AUTOSAR XML (schema 4-0-3)
package /AppMode/ApplicationSwComponentTypes
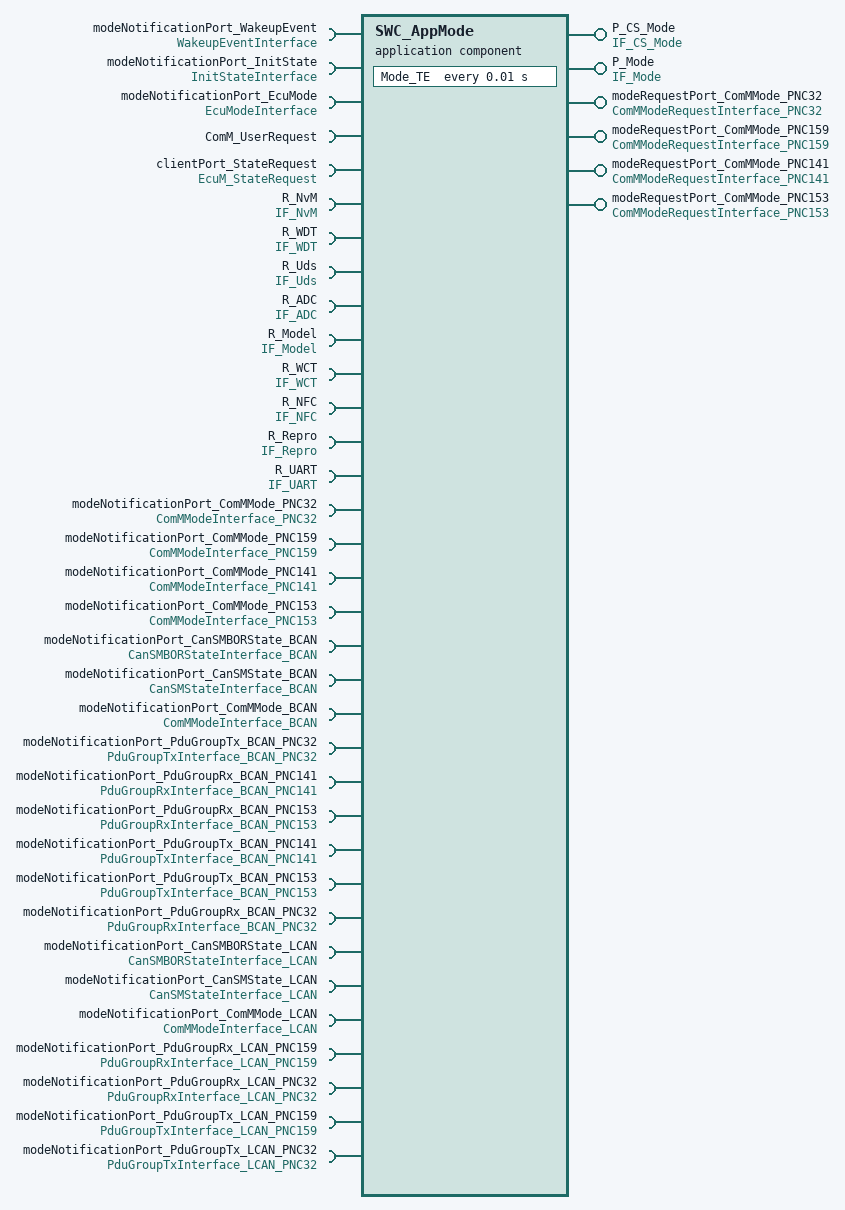
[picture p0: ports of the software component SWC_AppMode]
  application sw component type SWC_AppMode
    8 x require port:
      modeNotificationPort_WakeupEvent: mode-switch-receiver-com-spec{enhanced-mode-api=true, mode-group=WakeupEvent, supports-asynchronous-mode-switch=true}, required-interface=WakeupEventInterface
      modeNotificationPort_InitState: mode-switch-receiver-com-spec{enhanced-mode-api=true, mode-group=InitState, supports-asynchronous-mode-switch=true}, required-interface=InitStateInterface
      modeNotificationPort_EcuMode: mode-switch-receiver-com-spec{enhanced-mode-api=true, mode-group=EcuMode, supports-asynchronous-mode-switch=true}, required-interface=EcuModeInterface
      ComM_UserRequest: client-com-spec=GetCurrentComMode, required-interface=ComM_UserRequest
      clientPort_StateRequest: required-com-specs=[ReleaseRUN, RequestRUN, RequestSleep, RequestReset, RequestOff, SetRunState], required-interface=EcuM_StateRequest
      R_NvM: nonqueued-receiver-com-spec=NvM_STR, required-interface=IF_NvM
      R_WDT: nonqueued-receiver-com-spec=WDT_STR, required-interface=IF_WDT
      R_Uds: nonqueued-receiver-com-spec=Uds_STR, required-interface=IF_Uds
    provide port P_CS_Mode: provided-interface=IF_CS_Mode
      provided-com-specs:
        operation=ModeInit, queue-length=1
        operation=NvMInit, queue-length=1
        operation=ApplicationInit, queue-length=1
    provide port P_Mode: nonqueued-sender-com-spec=Mode_STR, provided-interface=IF_Mode
    7 x require port:
      R_ADC: nonqueued-receiver-com-spec=ADC_STR, required-interface=IF_ADC
      R_Model: nonqueued-receiver-com-spec=Model_STR, required-interface=IF_Model
      R_WCT: nonqueued-receiver-com-spec=WCT_STR, required-interface=IF_WCT
      R_NFC: nonqueued-receiver-com-spec=NFC_STR, required-interface=IF_NFC
      R_Repro: nonqueued-receiver-com-spec=Repro_STR, required-interface=IF_Repro
      R_UART: nonqueued-receiver-com-spec=UART_STR, required-interface=IF_UART
      modeNotificationPort_ComMMode_PNC32: mode-switch-receiver-com-spec{enhanced-mode-api=true, mode-group=ComMMode_PNC32, supports-asynchronous-mode-switch=true}, required-interface=ComMModeInterface_PNC32
    provide port modeRequestPort_ComMMode_PNC32: nonqueued-sender-com-spec=ComMMode_PNC32, provided-interface=ComMModeRequestInterface_PNC32
    require port modeNotificationPort_ComMMode_PNC159: mode-switch-receiver-com-spec{enhanced-mode-api=true, mode-group=ComMMode_PNC159, supports-asynchronous-mode-switch=true}, required-interface=ComMModeInterface_PNC159
    provide port modeRequestPort_ComMMode_PNC159: nonqueued-sender-com-spec=ComMMode_PNC159, provided-interface=ComMModeRequestInterface_PNC159
    require port modeNotificationPort_ComMMode_PNC141: mode-switch-receiver-com-spec{enhanced-mode-api=true, mode-group=ComMMode_PNC141, supports-asynchronous-mode-switch=true}, required-interface=ComMModeInterface_PNC141
    require port modeNotificationPort_ComMMode_PNC153: mode-switch-receiver-com-spec{enhanced-mode-api=true, mode-group=ComMMode_PNC153, supports-asynchronous-mode-switch=true}, required-interface=ComMModeInterface_PNC153
    provide port modeRequestPort_ComMMode_PNC141: nonqueued-sender-com-spec=ComMMode_PNC141, provided-interface=ComMModeRequestInterface_PNC141
    provide port modeRequestPort_ComMMode_PNC153: nonqueued-sender-com-spec=ComMMode_PNC153, provided-interface=ComMModeRequestInterface_PNC153
    16 x require port:
      modeNotificationPort_CanSMBORState_BCAN: mode-switch-receiver-com-spec{enhanced-mode-api=true, mode-group=CanSMBORState_BCAN, supports-asynchronous-mode-switch=true}, required-interface=CanSMBORStateInterface_BCAN
      modeNotificationPort_CanSMState_BCAN: mode-switch-receiver-com-spec{enhanced-mode-api=true, mode-group=CanSMState_BCAN, supports-asynchronous-mode-switch=true}, required-interface=CanSMStateInterface_BCAN
      modeNotificationPort_ComMMode_BCAN: mode-switch-receiver-com-spec{enhanced-mode-api=true, mode-group=ComMMode_BCAN, supports-asynchronous-mode-switch=true}, required-interface=ComMModeInterface_BCAN
      modeNotificationPort_PduGroupTx_BCAN_PNC32: mode-switch-receiver-com-spec{enhanced-mode-api=true, mode-group=PduGroupTx_BCAN_PNC32, supports-asynchronous-mode-switch=true}, required-interface=PduGroupTxInterface_BCAN_PNC32
      modeNotificationPort_PduGroupRx_BCAN_PNC141: mode-switch-receiver-com-spec{enhanced-mode-api=true, mode-group=PduGroupRx_BCAN_PNC141, supports-asynchronous-mode-switch=true}, required-interface=PduGroupRxInterface_BCAN_PNC141
      modeNotificationPort_PduGroupRx_BCAN_PNC153: mode-switch-receiver-com-spec{enhanced-mode-api=true, mode-group=PduGroupRx_BCAN_PNC153, supports-asynchronous-mode-switch=true}, required-interface=PduGroupRxInterface_BCAN_PNC153
      modeNotificationPort_PduGroupTx_BCAN_PNC141: mode-switch-receiver-com-spec{enhanced-mode-api=true, mode-group=PduGroupTx_BCAN_PNC141, supports-asynchronous-mode-switch=true}, required-interface=PduGroupTxInterface_BCAN_PNC141
      modeNotificationPort_PduGroupTx_BCAN_PNC153: mode-switch-receiver-com-spec{enhanced-mode-api=true, mode-group=PduGroupTx_BCAN_PNC153, supports-asynchronous-mode-switch=true}, required-interface=PduGroupTxInterface_BCAN_PNC153
      modeNotificationPort_PduGroupRx_BCAN_PNC32: mode-switch-receiver-com-spec{enhanced-mode-api=true, mode-group=PduGroupRx_BCAN_PNC32, supports-asynchronous-mode-switch=true}, required-interface=PduGroupRxInterface_BCAN_PNC32
      modeNotificationPort_CanSMBORState_LCAN: mode-switch-receiver-com-spec{enhanced-mode-api=true, mode-group=CanSMBORState_LCAN, supports-asynchronous-mode-switch=true}, required-interface=CanSMBORStateInterface_LCAN
      modeNotificationPort_CanSMState_LCAN: mode-switch-receiver-com-spec{enhanced-mode-api=true, mode-group=CanSMState_LCAN, supports-asynchronous-mode-switch=true}, required-interface=CanSMStateInterface_LCAN
      modeNotificationPort_ComMMode_LCAN: mode-switch-receiver-com-spec{enhanced-mode-api=true, mode-group=ComMMode_LCAN, supports-asynchronous-mode-switch=true}, required-interface=ComMModeInterface_LCAN
      modeNotificationPort_PduGroupRx_LCAN_PNC159: mode-switch-receiver-com-spec{enhanced-mode-api=true, mode-group=PduGroupRx_LCAN_PNC159, supports-asynchronous-mode-switch=true}, required-interface=PduGroupRxInterface_LCAN_PNC159
      modeNotificationPort_PduGroupRx_LCAN_PNC32: mode-switch-receiver-com-spec{enhanced-mode-api=true, mode-group=PduGroupRx_LCAN_PNC32, supports-asynchronous-mode-switch=true}, required-interface=PduGroupRxInterface_LCAN_PNC32
      modeNotificationPort_PduGroupTx_LCAN_PNC159: mode-switch-receiver-com-spec{enhanced-mode-api=true, mode-group=PduGroupTx_LCAN_PNC159, supports-asynchronous-mode-switch=true}, required-interface=PduGroupTxInterface_LCAN_PNC159
      modeNotificationPort_PduGroupTx_LCAN_PNC32: mode-switch-receiver-com-spec{enhanced-mode-api=true, mode-group=PduGroupTx_LCAN_PNC32, supports-asynchronous-mode-switch=true}, required-interface=PduGroupTxInterface_LCAN_PNC32
    behavior SwcIB_AppMode: data-type-mapping=[MAP_CanSMBORState, MAP_ComMMode_PNC, EcuModeMap, MAP_InitState, MAP_PduGroup, MAP_WakeupEvent, MAP_ComMMode, DataTypeMappingSet_WPC]
      23 x swc mode switch event, all with activation=ON-ENTRY:
        SMSE_Entry_BusOffStateSwitched_modeNotificationPort_CanSMBORState_BCAN_CanSMBORState_BCAN_COMPLETE: start-on-event=CanSMBORStateSwitched_BCAN, mode=modeNotificationPort_CanSMBORState_BCAN.CanSMBORState_BCAN.COMPLETE
        SMSE_Entry_BusOffStateSwitched_modeNotificationPort_CanSMBORState_BCAN_CanSMBORState_BCAN_START: start-on-event=CanSMBORStateSwitched_BCAN, mode=modeNotificationPort_CanSMBORState_BCAN.CanSMBORState_BCAN.START
        SMSE_Entry_BusOffStateSwitched_modeNotificationPort_CanSMBORState_LCAN_CanSMBORState_LCAN_COMPLETE: start-on-event=CanSMBORStateSwitched_LCAN, mode=modeNotificationPort_CanSMBORState_LCAN.CanSMBORState_LCAN.COMPLETE
        SMSE_Entry_BusOffStateSwitched_modeNotificationPort_CanSMBORState_LCAN_CanSMBORState_LCAN_START: start-on-event=CanSMBORStateSwitched_LCAN, mode=modeNotificationPort_CanSMBORState_LCAN.CanSMBORState_LCAN.START
        SMSE_Entry_ComMModeSwitched_PNC141_modeNotificationPort_ComMMode_PNC141_ComMMode_PNC141_PNC_REQUESTED: start-on-event=ComMModeSwitched_PNC141, mode=modeNotificationPort_ComMMode_PNC141.ComMMode_PNC141.PNC_REQUESTED
        SMSE_Entry_ComMModeSwitched_PNC141_modeNotificationPort_ComMMode_PNC141_ComMMode_PNC141_PNC_READY_SLEEP: start-on-event=ComMModeSwitched_PNC141, mode=modeNotificationPort_ComMMode_PNC141.ComMMode_PNC141.PNC_READY_SLEEP
        SMSE_Entry_ComMModeSwitched_PNC141_modeNotificationPort_ComMMode_PNC141_ComMMode_PNC141_PNC_PREPARE_SLEEP: start-on-event=ComMModeSwitched_PNC141, mode=modeNotificationPort_ComMMode_PNC141.ComMMode_PNC141.PNC_PREPARE_SLEEP
        SMSE_Entry_ComMModeSwitched_PNC141_modeNotificationPort_ComMMode_PNC141_ComMMode_PNC141_PNC_NO_COMMUNICATION: start-on-event=ComMModeSwitched_PNC141, mode=modeNotificationPort_ComMMode_PNC141.ComMMode_PNC141.PNC_NO_COMMUNICATION
        SMSE_Entry_EcuModeSwitched_modeNotificationPort_EcuMode_EcuMode_ECUM_STATE_RUN: start-on-event=EcuModeSwitched, mode=modeNotificationPort_EcuMode.EcuMode.ECUM_STATE_RUN
        SMSE_Entry_EcuModeSwitched_modeNotificationPort_EcuMode_EcuMode_ECUM_STATE_SHUTDOWN: start-on-event=EcuModeSwitched, mode=modeNotificationPort_EcuMode.EcuMode.ECUM_STATE_SHUTDOWN
        SMSE_Entry_EcuModeSwitched_modeNotificationPort_EcuMode_EcuMode_ECUM_STATE_PREP_SHUTDOWN: start-on-event=EcuModeSwitched, mode=modeNotificationPort_EcuMode.EcuMode.ECUM_STATE_PREP_SHUTDOWN
        SMSE_Entry_EcuModeSwitched_modeNotificationPort_EcuMode_EcuMode_ECUM_STATE_SLEEP: start-on-event=EcuModeSwitched, mode=modeNotificationPort_EcuMode.EcuMode.ECUM_STATE_SLEEP
        SMSE_Entry_EcuModeSwitched_modeNotificationPort_EcuMode_EcuMode_ECUM_STATE_OFF: start-on-event=EcuModeSwitched, mode=modeNotificationPort_EcuMode.EcuMode.ECUM_STATE_OFF
        SMSE_Entry_EcuModeSwitched_modeNotificationPort_EcuMode_EcuMode_ECUM_STATE_RESET: start-on-event=EcuModeSwitched, mode=modeNotificationPort_EcuMode.EcuMode.ECUM_STATE_RESET
        SMSE_Entry_InitCompleted_modeNotificationPort_InitState_InitState_COMPLETE: start-on-event=InitCompleted, mode=modeNotificationPort_InitState.InitState.COMPLETE
        SMSE_Entry_PduGroupSwitched_BCAN_PNC141_Rx_modeNotificationPort_PduGroupRx_BCAN_PNC141_PduGroupRx_BCAN_PNC141_STOP: start-on-event=PduGroupSwitched_BCAN_PNC141_Rx, mode=modeNotificationPort_PduGroupRx_BCAN_PNC141.PduGroupRx_BCAN_PNC141.STOP
        SMSE_Entry_PduGroupSwitched_BCAN_PNC141_Rx_modeNotificationPort_PduGroupRx_BCAN_PNC141_PduGroupRx_BCAN_PNC141_START: start-on-event=PduGroupSwitched_BCAN_PNC141_Rx, mode=modeNotificationPort_PduGroupRx_BCAN_PNC141.PduGroupRx_BCAN_PNC141.START
        SMSE_Entry_PduGroupSwitched_BCAN_PNC141_Tx_modeNotificationPort_PduGroupTx_BCAN_PNC141_PduGroupTx_BCAN_PNC141_STOP: start-on-event=PduGroupSwitched_BCAN_PNC141_Tx, mode=modeNotificationPort_PduGroupTx_BCAN_PNC141.PduGroupTx_BCAN_PNC141.STOP
        SMSE_Entry_PduGroupSwitched_BCAN_PNC141_Tx_modeNotificationPort_PduGroupTx_BCAN_PNC141_PduGroupTx_BCAN_PNC141_START: start-on-event=PduGroupSwitched_BCAN_PNC141_Tx, mode=modeNotificationPort_PduGroupTx_BCAN_PNC141.PduGroupTx_BCAN_PNC141.START
        SMSE_Entry_WakeupEventValidated_modeNotificationPort_WakeupEvent_WakeupEvent_BCAN_RX: start-on-event=WakeupEventValidated, mode=modeNotificationPort_WakeupEvent.WakeupEvent.BCAN_RX
        SMSE_Entry_WakeupEventValidated_modeNotificationPort_WakeupEvent_WakeupEvent_BCAN_RX_POLL: start-on-event=WakeupEventValidated, mode=modeNotificationPort_WakeupEvent.WakeupEvent.BCAN_RX_POLL
        SMSE_Entry_WakeupEventValidated_modeNotificationPort_WakeupEvent_WakeupEvent_LCAN_RX: start-on-event=WakeupEventValidated, mode=modeNotificationPort_WakeupEvent.WakeupEvent.LCAN_RX
        SMSE_Entry_WakeupEventValidated_modeNotificationPort_WakeupEvent_WakeupEvent_LCAN_RX_POLL: start-on-event=WakeupEventValidated, mode=modeNotificationPort_WakeupEvent.WakeupEvent.LCAN_RX_POLL
      timing event TE_Mode_TE: start-on-event=Mode_TE, period=0.01
      15 x swc mode switch event, all with activation=ON-ENTRY:
        SMSE_Entry_ComMModeSwitched_PNC153_modeNotificationPort_ComMMode_PNC153_ComMMode_PNC153_PNC_FULL_COMMUNICATION: start-on-event=ComMModeSwitched_PNC153, mode=modeNotificationPort_ComMMode_PNC153.ComMMode_PNC153.PNC_FULL_COMMUNICATION
        SMSE_Entry_ComMModeSwitched_PNC153_modeNotificationPort_ComMMode_PNC153_ComMMode_PNC153_PNC_NO_COMMUNICATION: start-on-event=ComMModeSwitched_PNC153, mode=modeNotificationPort_ComMMode_PNC153.ComMMode_PNC153.PNC_NO_COMMUNICATION
        SMSE_Entry_ComMModeSwitched_PNC153_modeNotificationPort_ComMMode_PNC153_ComMMode_PNC153_PNC_PREPARE_SLEEP: start-on-event=ComMModeSwitched_PNC153, mode=modeNotificationPort_ComMMode_PNC153.ComMMode_PNC153.PNC_PREPARE_SLEEP
        SMSE_Entry_ComMModeSwitched_PNC153_modeNotificationPort_ComMMode_PNC153_ComMMode_PNC153_PNC_READY_SLEEP: start-on-event=ComMModeSwitched_PNC153, mode=modeNotificationPort_ComMMode_PNC153.ComMMode_PNC153.PNC_READY_SLEEP
        SMSE_Entry_ComMModeSwitched_PNC153_modeNotificationPort_ComMMode_PNC153_ComMMode_PNC153_PNC_REQUESTED: start-on-event=ComMModeSwitched_PNC153, mode=modeNotificationPort_ComMMode_PNC153.ComMMode_PNC153.PNC_REQUESTED
        SMSE_Entry_PduGroupSwitched_BCAN_PNC153_Rx_modeNotificationPort_PduGroupRx_BCAN_PNC153_PduGroupRx_BCAN_PNC153_START: start-on-event=PduGroupSwitched_BCAN_PNC153_Rx, mode=modeNotificationPort_PduGroupRx_BCAN_PNC153.PduGroupRx_BCAN_PNC153.START
        SMSE_Entry_PduGroupSwitched_BCAN_PNC153_Rx_modeNotificationPort_PduGroupRx_BCAN_PNC153_PduGroupRx_BCAN_PNC153_STOP: start-on-event=PduGroupSwitched_BCAN_PNC153_Rx, mode=modeNotificationPort_PduGroupRx_BCAN_PNC153.PduGroupRx_BCAN_PNC153.STOP
        SMSE_Entry_PduGroupSwitched_BCAN_PNC153_Tx_modeNotificationPort_PduGroupTx_BCAN_PNC153_PduGroupTx_BCAN_PNC153_START: start-on-event=PduGroupSwitched_BCAN_PNC153_Tx, mode=modeNotificationPort_PduGroupTx_BCAN_PNC153.PduGroupTx_BCAN_PNC153.START
        SMSE_Entry_PduGroupSwitched_BCAN_PNC153_Tx_modeNotificationPort_PduGroupTx_BCAN_PNC153_PduGroupTx_BCAN_PNC153_STOP: start-on-event=PduGroupSwitched_BCAN_PNC153_Tx, mode=modeNotificationPort_PduGroupTx_BCAN_PNC153.PduGroupTx_BCAN_PNC153.STOP
        SMSE_Entry_ComMModeSwitched_BCAN_modeNotificationPort_ComMMode_BCAN_ComMMode_BCAN_FULL_COM: start-on-event=ComMModeSwitched_BCAN, mode=modeNotificationPort_ComMMode_BCAN.ComMMode_BCAN.FULL_COM
        SMSE_Entry_ComMModeSwitched_BCAN_modeNotificationPort_ComMMode_BCAN_ComMMode_BCAN_NO_COM: start-on-event=ComMModeSwitched_BCAN, mode=modeNotificationPort_ComMMode_BCAN.ComMMode_BCAN.NO_COM
        SMSE_Entry_ComMModeSwitched_BCAN_modeNotificationPort_ComMMode_BCAN_ComMMode_BCAN_SILENT_COM: start-on-event=ComMModeSwitched_BCAN, mode=modeNotificationPort_ComMMode_BCAN.ComMMode_BCAN.SILENT_COM
        SMSE_Entry_ComMModeSwitched_LCAN_modeNotificationPort_ComMMode_LCAN_ComMMode_LCAN_FULL_COM: start-on-event=ComMModeSwitched_LCAN, mode=modeNotificationPort_ComMMode_LCAN.ComMMode_LCAN.FULL_COM
        SMSE_Entry_ComMModeSwitched_LCAN_modeNotificationPort_ComMMode_LCAN_ComMMode_LCAN_NO_COM: start-on-event=ComMModeSwitched_LCAN, mode=modeNotificationPort_ComMMode_LCAN.ComMMode_LCAN.NO_COM
        SMSE_Entry_ComMModeSwitched_LCAN_modeNotificationPort_ComMMode_LCAN_ComMMode_LCAN_SILENT_COM: start-on-event=ComMModeSwitched_LCAN, mode=modeNotificationPort_ComMMode_LCAN.ComMMode_LCAN.SILENT_COM
      operation invoked event OIE_Mode_CS_ApplicationInit_P_CS_Mode_ApplicationInit: start-on-event=Mode_CS_ApplicationInit, operation=P_CS_Mode.ApplicationInit
      operation invoked event OIE_Mode_CS_ModeInit_P_CS_Mode_ModeInit: start-on-event=Mode_CS_ModeInit, operation=P_CS_Mode.ModeInit
      operation invoked event OIE_Mode_CS_NvMInit_P_CS_Mode_NvMInit: start-on-event=Mode_CS_NvMInit, operation=P_CS_Mode.NvMInit
      24 x swc mode switch event, all with activation=ON-ENTRY:
        SMSE_Entry_WakeupEventValidated_modeNotificationPort_WakeupEvent_WakeupEvent_IGN1: start-on-event=WakeupEventValidated, mode=modeNotificationPort_WakeupEvent.WakeupEvent.IGN1
        SMSE_Entry_ComMModeSwitched_PNC159_modeNotificationPort_ComMMode_PNC159_ComMMode_PNC159_PNC_FULL_COMMUNICATION: start-on-event=ComMModeSwitched_PNC159, mode=modeNotificationPort_ComMMode_PNC159.ComMMode_PNC159.PNC_FULL_COMMUNICATION
        SMSE_Entry_ComMModeSwitched_PNC159_modeNotificationPort_ComMMode_PNC159_ComMMode_PNC159_PNC_NO_COMMUNICATION: start-on-event=ComMModeSwitched_PNC159, mode=modeNotificationPort_ComMMode_PNC159.ComMMode_PNC159.PNC_NO_COMMUNICATION
        SMSE_Entry_ComMModeSwitched_PNC159_modeNotificationPort_ComMMode_PNC159_ComMMode_PNC159_PNC_PREPARE_SLEEP: start-on-event=ComMModeSwitched_PNC159, mode=modeNotificationPort_ComMMode_PNC159.ComMMode_PNC159.PNC_PREPARE_SLEEP
        SMSE_Entry_ComMModeSwitched_PNC159_modeNotificationPort_ComMMode_PNC159_ComMMode_PNC159_PNC_READY_SLEEP: start-on-event=ComMModeSwitched_PNC159, mode=modeNotificationPort_ComMMode_PNC159.ComMMode_PNC159.PNC_READY_SLEEP
        SMSE_Entry_ComMModeSwitched_PNC159_modeNotificationPort_ComMMode_PNC159_ComMMode_PNC159_PNC_REQUESTED: start-on-event=ComMModeSwitched_PNC159, mode=modeNotificationPort_ComMMode_PNC159.ComMMode_PNC159.PNC_REQUESTED
        SMSE_Entry_ComMModeSwitched_PNC141_modeNotificationPort_ComMMode_PNC141_ComMMode_PNC141_PNC_FULL_COMMUNICATION: start-on-event=ComMModeSwitched_PNC141, mode=modeNotificationPort_ComMMode_PNC141.ComMMode_PNC141.PNC_FULL_COMMUNICATION
        SMSE_Entry_PduGroupSwitched_LCAN_PNC159_Rx_modeNotificationPort_PduGroupRx_LCAN_PNC159_PduGroupRx_LCAN_PNC159_START: start-on-event=PduGroupSwitched_LCAN_PNC159_Rx, mode=modeNotificationPort_PduGroupRx_LCAN_PNC159.PduGroupRx_LCAN_PNC159.START
        SMSE_Entry_PduGroupSwitched_LCAN_PNC159_Rx_modeNotificationPort_PduGroupRx_LCAN_PNC159_PduGroupRx_LCAN_PNC159_STOP: start-on-event=PduGroupSwitched_LCAN_PNC159_Rx, mode=modeNotificationPort_PduGroupRx_LCAN_PNC159.PduGroupRx_LCAN_PNC159.STOP
        SMSE_Entry_PduGroupSwitched_LCAN_PNC159_Tx_modeNotificationPort_PduGroupTx_LCAN_PNC159_PduGroupTx_LCAN_PNC159_START: start-on-event=PduGroupSwitched_LCAN_PNC159_Tx, mode=modeNotificationPort_PduGroupTx_LCAN_PNC159.PduGroupTx_LCAN_PNC159.START
        SMSE_Entry_PduGroupSwitched_LCAN_PNC159_Tx_modeNotificationPort_PduGroupTx_LCAN_PNC159_PduGroupTx_LCAN_PNC159_STOP: start-on-event=PduGroupSwitched_LCAN_PNC159_Tx, mode=modeNotificationPort_PduGroupTx_LCAN_PNC159.PduGroupTx_LCAN_PNC159.STOP
        SMSE_Entry_ComMModeSwitched_PNC32_modeNotificationPort_ComMMode_PNC32_ComMMode_PNC32_PNC_FULL_COMMUNICATION: start-on-event=ComMModeSwitched_PNC32, mode=modeNotificationPort_ComMMode_PNC32.ComMMode_PNC32.PNC_FULL_COMMUNICATION
        SMSE_Entry_ComMModeSwitched_PNC32_modeNotificationPort_ComMMode_PNC32_ComMMode_PNC32_PNC_NO_COMMUNICATION: start-on-event=ComMModeSwitched_PNC32, mode=modeNotificationPort_ComMMode_PNC32.ComMMode_PNC32.PNC_NO_COMMUNICATION
        SMSE_Entry_ComMModeSwitched_PNC32_modeNotificationPort_ComMMode_PNC32_ComMMode_PNC32_PNC_PREPARE_SLEEP: start-on-event=ComMModeSwitched_PNC32, mode=modeNotificationPort_ComMMode_PNC32.ComMMode_PNC32.PNC_PREPARE_SLEEP
        SMSE_Entry_ComMModeSwitched_PNC32_modeNotificationPort_ComMMode_PNC32_ComMMode_PNC32_PNC_READY_SLEEP: start-on-event=ComMModeSwitched_PNC32, mode=modeNotificationPort_ComMMode_PNC32.ComMMode_PNC32.PNC_READY_SLEEP
        SMSE_Entry_ComMModeSwitched_PNC32_modeNotificationPort_ComMMode_PNC32_ComMMode_PNC32_PNC_REQUESTED: start-on-event=ComMModeSwitched_PNC32, mode=modeNotificationPort_ComMMode_PNC32.ComMMode_PNC32.PNC_REQUESTED
        SMSE_Entry_PduGroupSwitched_BCAN_PNC32_Rx_modeNotificationPort_PduGroupRx_BCAN_PNC32_PduGroupRx_BCAN_PNC32_START: start-on-event=PduGroupSwitched_BCAN_PNC32_Rx, mode=modeNotificationPort_PduGroupRx_BCAN_PNC32.PduGroupRx_BCAN_PNC32.START
        SMSE_Entry_PduGroupSwitched_BCAN_PNC32_Rx_modeNotificationPort_PduGroupRx_BCAN_PNC32_PduGroupRx_BCAN_PNC32_STOP: start-on-event=PduGroupSwitched_BCAN_PNC32_Rx, mode=modeNotificationPort_PduGroupRx_BCAN_PNC32.PduGroupRx_BCAN_PNC32.STOP
        SMSE_Entry_PduGroupSwitched_BCAN_PNC32_Tx_modeNotificationPort_PduGroupTx_BCAN_PNC32_PduGroupTx_BCAN_PNC32_START: start-on-event=PduGroupSwitched_BCAN_PNC32_Tx, mode=modeNotificationPort_PduGroupTx_BCAN_PNC32.PduGroupTx_BCAN_PNC32.START
        SMSE_Entry_PduGroupSwitched_BCAN_PNC32_Tx_modeNotificationPort_PduGroupTx_BCAN_PNC32_PduGroupTx_BCAN_PNC32_STOP: start-on-event=PduGroupSwitched_BCAN_PNC32_Tx, mode=modeNotificationPort_PduGroupTx_BCAN_PNC32.PduGroupTx_BCAN_PNC32.STOP
        SMSE_Entry_PduGroupSwitched_LCAN_PNC32_Tx_modeNotificationPort_PduGroupTx_LCAN_PNC32_PduGroupTx_LCAN_PNC32_START: start-on-event=PduGroupSwitched_LCAN_PNC32_Tx, mode=modeNotificationPort_PduGroupTx_LCAN_PNC32.PduGroupTx_LCAN_PNC32.START
        SMSE_Entry_PduGroupSwitched_LCAN_PNC32_Tx_modeNotificationPort_PduGroupTx_LCAN_PNC32_PduGroupTx_LCAN_PNC32_STOP: start-on-event=PduGroupSwitched_LCAN_PNC32_Tx, mode=modeNotificationPort_PduGroupTx_LCAN_PNC32.PduGroupTx_LCAN_PNC32.STOP
        SMSE_Entry_PduGroupSwitched_LCAN_PNC32_Rx_modeNotificationPort_PduGroupRx_LCAN_PNC32_PduGroupRx_LCAN_PNC32_START: start-on-event=PduGroupSwitched_LCAN_PNC32_Rx, mode=modeNotificationPort_PduGroupRx_LCAN_PNC32.PduGroupRx_LCAN_PNC32.START
        SMSE_Entry_PduGroupSwitched_LCAN_PNC32_Rx_modeNotificationPort_PduGroupRx_LCAN_PNC32_PduGroupRx_LCAN_PNC32_STOP: start-on-event=PduGroupSwitched_LCAN_PNC32_Rx, mode=modeNotificationPort_PduGroupRx_LCAN_PNC32.PduGroupRx_LCAN_PNC32.STOP
      25 x runnable:
        Mode_TE: symbol=Mode_TE_Runnable
          data-receive-point-by-arguments:
            9 x access, all with scope=COMMUNICATION-INTER-ECU:
              DRPBA_Mode_TE_R_ADC_ADC_STR: accessed-variable=R_ADC.ADC_STR
              DRPBA_Mode_TE_R_Model_Model_COMM_STR: accessed-variable=R_Model.Model_STR
              DRPBA_Mode_TE_R_NFC_NFC2_STR: accessed-variable=R_NFC.NFC_STR
              DRPBA_Mode_TE_R_WCT_WCT_STR: accessed-variable=R_WCT.WCT_STR
              DRPBA_Mode_TE_R_Uds_Uds_STR: accessed-variable=R_Uds.Uds_STR
              DRPBA_Mode_TE_R_WDT_WDT_STR: accessed-variable=R_WDT.WDT_STR
              DRPBA_Mode_TE_R_Repro_Repro_STR: accessed-variable=R_Repro.Repro_STR
              DRPBA_Mode_TE_R_NvM_NvM_STR: accessed-variable=R_NvM.NvM_STR
              DRPBA_Mode_TE_R_UART_UART_STR: accessed-variable=R_UART.UART_STR
          data-send-points:
            4 x access, all with scope=COMMUNICATION-INTER-ECU:
              DSP_Mode_TE_modeRequestPort_ComMMode_PNC141_ComMMode_PNC141: accessed-variable=modeRequestPort_ComMMode_PNC141.ComMMode_PNC141
              DSP_Mode_TE_modeRequestPort_ComMMode_PNC153_ComMMode_PNC153: accessed-variable=modeRequestPort_ComMMode_PNC153.ComMMode_PNC153
              DSP_Mode_TE_P_Mode_Mode_STR: accessed-variable=P_Mode.Mode_STR
              DSP_Mode_TE_modeRequestPort_ComMMode_PNC159_ComMMode_PNC159: accessed-variable=modeRequestPort_ComMMode_PNC159.ComMMode_PNC159
          9 x sync call:
            SSCP_Mode_TE_ComM_UserRequest_GetCurrentComMode: operation=ComM_UserRequest.GetCurrentComMode
            SSCP_Mode_TE_ComM_UserRequest_GetRequestedComMode: operation=ComM_UserRequest.GetRequestedComMode
            SSCP_Mode_TE_ComM_UserRequest_RequestComMode: operation=ComM_UserRequest.RequestComMode
            SSCP_Mode_TE_clientPort_StateRequest_ReleaseRUN: operation=clientPort_StateRequest.ReleaseRUN
            SSCP_Mode_TE_clientPort_StateRequest_RequestOff: operation=clientPort_StateRequest.RequestOff
            SSCP_Mode_TE_clientPort_StateRequest_RequestRUN: operation=clientPort_StateRequest.RequestRUN, timeout=0.0
            SSCP_Mode_TE_clientPort_StateRequest_RequestReset: operation=clientPort_StateRequest.RequestReset
            SSCP_Mode_TE_clientPort_StateRequest_RequestSleep: operation=clientPort_StateRequest.RequestSleep
            SSCP_Mode_TE_clientPort_StateRequest_SetRunState: operation=clientPort_StateRequest.SetRunState, timeout=0.0
        EcuModeSwitched: can-be-invoked-concurrently=true, symbol=AppMode_EcuModeSwitched
          data-send-points:
            access DSP_EcuModeSwitched_modeRequestPort_ComMMode_PNC141_ComMMode_PNC141: accessed-variable=modeRequestPort_ComMMode_PNC141.ComMMode_PNC141, scope=COMMUNICATION-INTER-ECU
            access DSP_EcuModeSwitched_modeRequestPort_ComMMode_PNC153_ComMMode_PNC153: accessed-variable=modeRequestPort_ComMMode_PNC153.ComMMode_PNC153, scope=COMMUNICATION-INTER-ECU
            access DSP_EcuModeSwitched_modeRequestPort_ComMMode_PNC159_ComMMode_PNC159: accessed-variable=modeRequestPort_ComMMode_PNC159.ComMMode_PNC159, scope=COMMUNICATION-INTER-ECU
          mode-access-point mode-group=modeNotificationPort_EcuMode.EcuMode:
            ident MRAP_EcuModeSwitched_modeNotificationPort_EcuMode_EcuMode
          sync call SSCP_EcuModeSwitched_clientPort_StateRequest_RequestRUN: operation=clientPort_StateRequest.RequestRUN
          sync call SSCP_EcuModeSwitched_clientPort_StateRequest_SetRunState: operation=clientPort_StateRequest.SetRunState
        WakeupEventValidated: can-be-invoked-concurrently=true, symbol=AppMode_WakeupEventValidated
          data-send-points:
            access DSP_WakeupEventValidated_modeRequestPort_ComMMode_PNC141_ComMMode_PNC141: accessed-variable=modeRequestPort_ComMMode_PNC141.ComMMode_PNC141, scope=COMMUNICATION-INTER-ECU
            access DSP_WakeupEventValidated_modeRequestPort_ComMMode_PNC153_ComMMode_PNC153: accessed-variable=modeRequestPort_ComMMode_PNC153.ComMMode_PNC153, scope=COMMUNICATION-INTER-ECU
            access DSP_WakeupEventValidated_modeRequestPort_ComMMode_PNC159_ComMMode_PNC159: accessed-variable=modeRequestPort_ComMMode_PNC159.ComMMode_PNC159, scope=COMMUNICATION-INTER-ECU
          mode-access-point mode-group=modeNotificationPort_WakeupEvent.WakeupEvent:
            ident MRAP_WakeupEventValidated_modeNotificationPort_WakeupEvent_WakeupEvent
          sync call SSCP_WakeupEventValidated_clientPort_StateRequest_RequestRUN: operation=clientPort_StateRequest.RequestRUN, timeout=0.0
        CanSMBORStateSwitched_BCAN: can-be-invoked-concurrently=true, symbol=AppMode_CanSMBORStateSwitched_BCAN
          mode-access-point mode-group=modeNotificationPort_CanSMBORState_BCAN.CanSMBORState_BCAN:
            ident MRAP_BusStateSwitched_modeNotificationPort_CanSMBORState_BCAN_CanSMBORState_BCAN
        CanSMBORStateSwitched_LCAN: can-be-invoked-concurrently=true, symbol=AppMode_CanSMBORStateSwitched_LCAN
          mode-access-point mode-group=modeNotificationPort_CanSMBORState_LCAN.CanSMBORState_LCAN:
            ident MRAP_BusStateSwitched_modeNotificationPort_CanSMBORState_LCAN_CanSMBORState_LCAN
        ComMModeSwitched_PNC159: can-be-invoked-concurrently=true, symbol=AppMode_ComMModeSwitched_PNC159
          mode-access-point mode-group=modeNotificationPort_ComMMode_PNC159.ComMMode_PNC159:
            ident MRAP_ComMModeSwitched_PNC159_modeNotificationPort_ComMMode_PNC159_ComMMode_PNC159
        ComMModeSwitched_PNC141: can-be-invoked-concurrently=true, symbol=AppMode_ComMModeSwitched_PNC141
          mode-access-point mode-group=modeNotificationPort_ComMMode_PNC141.ComMMode_PNC141:
            ident MRAP_ComMModeSwitched_PNC141_modeNotificationPort_ComMMode_PNC141_ComMMode_PNC141
        ComMModeSwitched_PNC153: can-be-invoked-concurrently=true, symbol=AppMode_ComMModeSwitched_PNC153
          mode-access-point mode-group=modeNotificationPort_ComMMode_PNC153.ComMMode_PNC153:
            ident MRAP_ComMModeSwitched_PNC153_modeNotificationPort_ComMMode_PNC153_ComMMode_PNC153
        InitCompleted: can-be-invoked-concurrently=true, symbol=AppMode_InitCompleted
          mode-access-point mode-group=modeNotificationPort_InitState.InitState:
            ident MRAP_InitCompleted_modeNotificationPort_InitState_InitState
        PduGroupSwitched_LCAN_PNC159_Rx: can-be-invoked-concurrently=true, symbol=AppMode_PduGroupSwitched_LCAN_PNC159_Rx
          mode-access-point mode-group=modeNotificationPort_PduGroupRx_LCAN_PNC159.PduGroupRx_LCAN_PNC159:
            ident MRAP_PduGroupSwitched_LCAN_PNC159_Rx_modeNotificationPort_PduGroupRx_LCAN_PNC159_PduGroupRx_LCAN_PNC159
        PduGroupSwitched_BCAN_PNC141_Rx: can-be-invoked-concurrently=true, symbol=AppMode_PduGroupSwitched_BCAN_PNC141_Rx
          mode-access-point mode-group=modeNotificationPort_PduGroupRx_BCAN_PNC141.PduGroupRx_BCAN_PNC141:
            ident MRAP_PduGroupSwitched_modeNotificationPort_PduGroupRx_BCAN_PNC141_PduGroupRx_BCAN_PNC141
        PduGroupSwitched_BCAN_PNC153_Rx: can-be-invoked-concurrently=true, symbol=AppMode_PduGroupSwitched_BCAN_PNC153_Rx
          mode-access-point mode-group=modeNotificationPort_PduGroupRx_BCAN_PNC153.PduGroupRx_BCAN_PNC153:
            ident MRAP_PduGroupSwitched_BCAN_PNC153_Rx_modeNotificationPort_PduGroupRx_BCAN_PNC153_PduGroupRx_BCAN_PNC153
        PduGroupSwitched_LCAN_PNC159_Tx: can-be-invoked-concurrently=true, symbol=AppMode_PduGroupSwitched_LCAN_PNC159_Tx
          mode-access-point mode-group=modeNotificationPort_PduGroupTx_LCAN_PNC159.PduGroupTx_LCAN_PNC159:
            ident MRAP_PduGroupSwitched_LCAN_PNC159_Tx_modeNotificationPort_PduGroupTx_LCAN_PNC159_PduGroupTx_LCAN_PNC159
        PduGroupSwitched_BCAN_PNC141_Tx: can-be-invoked-concurrently=true, symbol=AppMode_PduGroupSwitched_BCAN_PNC141_Tx
          mode-access-point mode-group=modeNotificationPort_PduGroupTx_BCAN_PNC141.PduGroupTx_BCAN_PNC141:
            ident MRAP_PduGroupSwitched_modeNotificationPort_PduGroupTx_BCAN_PNC141_PduGroupTx_BCAN_PNC141
        PduGroupSwitched_BCAN_PNC153_Tx: can-be-invoked-concurrently=true, symbol=AppMode_PduGroupSwitched_BCAN_PNC153_Tx
          mode-access-point mode-group=modeNotificationPort_PduGroupTx_BCAN_PNC153.PduGroupTx_BCAN_PNC153:
            ident MRAP_PduGroupSwitched_BCAN_PNC153_Tx_modeNotificationPort_PduGroupTx_BCAN_PNC153_PduGroupTx_BCAN_PNC153
        ComMModeSwitched_BCAN: can-be-invoked-concurrently=true, symbol=AppMode_ComMModeSwitched_BCAN_Runnable
          mode-access-point mode-group=modeNotificationPort_ComMMode_BCAN.ComMMode_BCAN:
            ident MRAP_ComMModeSwitched_BCAN_modeNotificationPort_ComMMode_BCAN_ComMMode_BCAN
        ComMModeSwitched_LCAN: can-be-invoked-concurrently=true, symbol=AppMode_ComMModeSwitched_LCAN_Runnable
          mode-access-point mode-group=modeNotificationPort_ComMMode_LCAN.ComMMode_LCAN:
            ident MRAP_ComMModeSwitched_LCAN_modeNotificationPort_ComMMode_LCAN_ComMMode_LCAN
        Mode_CS_ApplicationInit: can-be-invoked-concurrently=true, symbol=Mode_CS_ApplicationInit_Runnable
        Mode_CS_ModeInit: can-be-invoked-concurrently=true, symbol=Mode_CS_ModeInit_Runnable
        Mode_CS_NvMInit: can-be-invoked-concurrently=true, symbol=Mode_CS_NvMInit_Runnable
        ComMModeSwitched_PNC32: can-be-invoked-concurrently=true, symbol=AppMode_ComMModeSwitched_PNC32
          mode-access-point mode-group=modeNotificationPort_ComMMode_PNC32.ComMMode_PNC32:
            ident MRAP_ComMModeSwitched_PNC32_modeNotificationPort_ComMMode_PNC32_ComMMode_PNC32
        PduGroupSwitched_BCAN_PNC32_Rx: can-be-invoked-concurrently=true, symbol=AppMode_PduGroupSwitched_BCAN_PNC32_Rx
          mode-access-point mode-group=modeNotificationPort_PduGroupRx_BCAN_PNC32.PduGroupRx_BCAN_PNC32:
            ident MRAP_PduGroupSwitched_BCAN_PNC32_Rx_modeNotificationPort_PduGroupRx_BCAN_PNC32_PduGroupRx_BCAN_PNC32
        PduGroupSwitched_BCAN_PNC32_Tx: can-be-invoked-concurrently=true, symbol=AppMode_PduGroupSwitched_BCAN_PNC32_Tx
          mode-access-point mode-group=modeNotificationPort_PduGroupTx_BCAN_PNC32.PduGroupTx_BCAN_PNC32:
            ident MRAP_PduGroupSwitched_BCAN_PNC32_Tx_modeNotificationPort_PduGroupTx_BCAN_PNC32_PduGroupTx_BCAN_PNC32
        PduGroupSwitched_LCAN_PNC32_Tx: can-be-invoked-concurrently=true, symbol=AppMode_PduGroupSwitched_LCAN_PNC32_Tx
          mode-access-point mode-group=modeNotificationPort_PduGroupTx_LCAN_PNC32.PduGroupTx_LCAN_PNC32:
            ident MRAP_PduGroupSwitched_LCAN_PNC32_Tx_modeNotificationPort_PduGroupTx_LCAN_PNC32_PduGroupTx_LCAN_PNC32
        PduGroupSwitched_LCAN_PNC32_Rx: can-be-invoked-concurrently=true, symbol=AppMode_PduGroupSwitched_LCAN_PNC32_Rx
          mode-access-point mode-group=modeNotificationPort_PduGroupRx_LCAN_PNC32.PduGroupRx_LCAN_PNC32:
            ident MRAP_PduGroupSwitched_LCAN_PNC32_Rx_modeNotificationPort_PduGroupRx_LCAN_PNC32_PduGroupRx_LCAN_PNC32
      swc service dependency SwcServiceDependency_BswM
        assigned-ports:
          port-prototype=modeNotificationPort_WakeupEvent, role=Custom
          port-prototype=modeNotificationPort_InitState, role=Custom
          port-prototype=modeNotificationPort_EcuMode, role=Custom
          port-prototype=modeNotificationPort_ComMMode_PNC32, role=Custom
          port-prototype=modeRequestPort_ComMMode_PNC32, role=Custom
          port-prototype=modeNotificationPort_ComMMode_PNC159, role=Custom
          port-prototype=modeRequestPort_ComMMode_PNC159, role=Custom
          port-prototype=modeNotificationPort_ComMMode_PNC141, role=Custom
          port-prototype=modeNotificationPort_ComMMode_PNC153, role=Custom
          port-prototype=modeRequestPort_ComMMode_PNC141, role=Custom
          port-prototype=modeRequestPort_ComMMode_PNC153, role=Custom
          port-prototype=modeNotificationPort_CanSMBORState_BCAN, role=Custom
          port-prototype=modeNotificationPort_CanSMState_BCAN, role=Custom
          port-prototype=modeNotificationPort_ComMMode_BCAN, role=Custom
          port-prototype=modeNotificationPort_PduGroupTx_BCAN_PNC32, role=Custom
          port-prototype=modeNotificationPort_PduGroupRx_BCAN_PNC141, role=Custom
          port-prototype=modeNotificationPort_PduGroupRx_BCAN_PNC153, role=Custom
          port-prototype=modeNotificationPort_PduGroupTx_BCAN_PNC141, role=Custom
          port-prototype=modeNotificationPort_PduGroupTx_BCAN_PNC153, role=Custom
          port-prototype=modeNotificationPort_PduGroupRx_BCAN_PNC32, role=Custom
          port-prototype=modeNotificationPort_CanSMBORState_LCAN, role=Custom
          port-prototype=modeNotificationPort_CanSMState_LCAN, role=Custom
          port-prototype=modeNotificationPort_ComMMode_LCAN, role=Custom
          port-prototype=modeNotificationPort_PduGroupRx_LCAN_PNC159, role=Custom
          port-prototype=modeNotificationPort_PduGroupRx_LCAN_PNC32, role=Custom
          port-prototype=modeNotificationPort_PduGroupTx_LCAN_PNC159, role=Custom
          port-prototype=modeNotificationPort_PduGroupTx_LCAN_PNC32, role=Custom
        service-needs:
          bsw mgr needs BswMgrNeeds
  client server interface IF_CS_Mode
    operation ModeInit
      arg BswInit: type=uint8, direction=OUT, server-argument-impl-policy=USE-ARGUMENT-TYPE
    operation NvMInit
      arg NvMInit: type=uint8, direction=IN, server-argument-impl-policy=USE-ARGUMENT-TYPE
    operation ApplicationInit
      arg AppInit: type=uint8, direction=OUT, server-argument-impl-policy=USE-ARGUMENT-TYPE
  sender receiver interface IF_Mode  # NFC SWC Output
    data Mode_STR: type=IDT_Mode_STR
